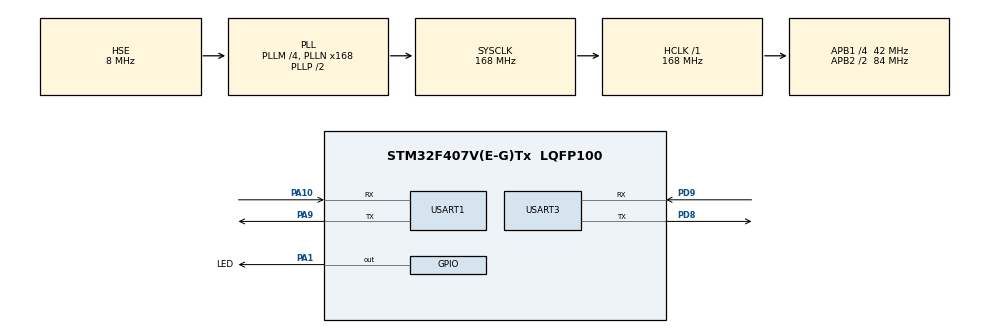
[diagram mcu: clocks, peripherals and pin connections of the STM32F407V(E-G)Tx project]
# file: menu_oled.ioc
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Mcu.Family=STM32F4
Mcu.Name=STM32F407V(E-G)Tx
Mcu.Package=LQFP100
NVIC.PriorityGroup=NVIC_PRIORITYGROUP_4
NVIC.TIM6_DAC_IRQn=true\:0\:0\:false\:false\:true\:true\:true
NVIC.TIM7_IRQn=true\:0\:0\:false\:false\:true\:true\:true
NVIC.USART3_IRQn=true\:0\:0\:false\:false\:true\:true\:true
PA1.GPIO_Label=LED
PA1.Signal=GPIO_Output
PA10.Mode=Asynchronous
PA10.Signal=USART1_RX
PA13.Mode=Serial_Wire
PA13.Signal=SYS_JTMS-SWDIO
PA14.Mode=Serial_Wire
PA14.Signal=SYS_JTCK-SWCLK
PA9.Mode=Asynchronous
PA9.Signal=USART1_TX
PC14-OSC32_IN.Mode=LSE-External-Oscillator
PC14-OSC32_IN.Signal=RCC_OSC32_IN
PC15-OSC32_OUT.Mode=LSE-External-Oscillator
PC15-OSC32_OUT.Signal=RCC_OSC32_OUT
PD8.Mode=Asynchronous
PD8.Signal=USART3_TX
PD9.Mode=Asynchronous
PD9.Signal=USART3_RX
PH0-OSC_IN.Mode=HSE-External-Oscillator
PH0-OSC_IN.Signal=RCC_OSC_IN
PH1-OSC_OUT.Mode=HSE-External-Oscillator
PH1-OSC_OUT.Signal=RCC_OSC_OUT
ProjectManager.HeapSize=0x200
ProjectManager.StackSize=0x1000
ProjectManager.TargetToolchain=MDK-ARM V5.27
RCC.48MHZClocksFreq_Value=48000000
RCC.AHBFreq_Value=168000000
RCC.APB1CLKDivider=RCC_HCLK_DIV4
RCC.APB1Freq_Value=42000000
RCC.APB1TimFreq_Value=84000000
RCC.APB2CLKDivider=RCC_HCLK_DIV2
RCC.APB2Freq_Value=84000000
RCC.APB2TimFreq_Value=168000000
RCC.CortexFreq_Value=168000000
RCC.HCLKFreq_Value=168000000
RCC.HSE_VALUE=8000000
RCC.HSI_VALUE=16000000
RCC.PLLM=4
RCC.PLLN=168
RCC.PLLQ=7
RCC.PLLSourceVirtual=RCC_PLLSOURCE_HSE
RCC.SYSCLKFreq_VALUE=168000000
RCC.SYSCLKSource=RCC_SYSCLKSOURCE_PLLCLK
RCC.VCOOutputFreq_Value=336000000
TIM6.Period=10000
TIM6.Prescaler=83
TIM7.Period=50000
TIM7.Prescaler=83
USART1.VirtualMode=VM_ASYNC
USART3.VirtualMode=VM_ASYNC
VP_RTC_VS_RTC_Activate.Mode=RTC_Enabled
VP_TIM6_VS_ClockSourceINT.Mode=Enable_Timer
VP_TIM7_VS_ClockSourceINT.Mode=Enable_Timer
board=custom

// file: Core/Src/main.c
/* USER CODE BEGIN Header */
/**
  ******************************************************************************
  * @file           : main.c
  * @brief          : Main program body
  ******************************************************************************
  * @attention
  *
  * <h2><center>&copy; Copyright (c) 2021 STMicroelectronics.
  * All rights reserved.</center></h2>
  *
  * This software component is licensed by ST under BSD 3-Clause license,
  * the "License"; You may not use this file except in compliance with the
  * License. You may obtain a copy of the License at:
  *                        opensource.org/licenses/BSD-3-Clause
  *
  ******************************************************************************
  */
/* USER CODE END Header */
#include "main.h"
#include "rtc.h"
#include "tim.h"
#include "usart.h"
#include "gpio.h"
#include "myiic.h"
#include "oled12832.h"
#include "menu.h"

void SystemClock_Config(void);

int main(void)
{

  /* MCU Configuration--------------------------------------------------------*/

  /* Reset of all peripherals, Initializes the Flash interface and the Systick. */
  HAL_Init();

  /* Configure the system clock */
  SystemClock_Config();

  /* Initialize all configured peripherals */
  MX_GPIO_Init();
  MX_USART1_UART_Init();
  MX_TIM7_Init();
  MX_TIM6_Init();
  MX_USART3_UART_Init();
  MX_RTC_Init();
  /* USER CODE BEGIN 2 */
  MyIIC_Init();
  OLED_Init();
  OLED_Clear();
  MenuInit();
  /* USER CODE END 2 */

  /* Infinite loop */
  while (1)
  {

    /* USER CODE BEGIN 3 */
    HAL_Delay(500);
    caidan();
  }
  /* USER CODE END 3 */
}

void SystemClock_Config(void)
{
  RCC_OscInitTypeDef RCC_OscInitStruct = {0};
  RCC_ClkInitTypeDef RCC_ClkInitStruct = {0};
  RCC_PeriphCLKInitTypeDef PeriphClkInitStruct = {0};

  /** Configure the main internal regulator output voltage
  */
  __HAL_RCC_PWR_CLK_ENABLE();
  __HAL_PWR_VOLTAGESCALING_CONFIG(PWR_REGULATOR_VOLTAGE_SCALE1);
  /** Initializes the RCC Oscillators according to the specified parameters
  * in the RCC_OscInitTypeDef structure.
  */
  RCC_OscInitStruct.OscillatorType = RCC_OSCILLATORTYPE_LSI|RCC_OSCILLATORTYPE_HSE;
  RCC_OscInitStruct.HSEState = RCC_HSE_ON;
  RCC_OscInitStruct.LSIState = RCC_LSI_ON;
  RCC_OscInitStruct.PLL.PLLState = RCC_PLL_ON;
  RCC_OscInitStruct.PLL.PLLSource = RCC_PLLSOURCE_HSE;
  RCC_OscInitStruct.PLL.PLLM = 4;
  RCC_OscInitStruct.PLL.PLLN = 168;
  RCC_OscInitStruct.PLL.PLLP = RCC_PLLP_DIV2;
  RCC_OscInitStruct.PLL.PLLQ = 7;
  if (HAL_RCC_OscConfig(&RCC_OscInitStruct) != HAL_OK)
  {
    Error_Handler();
  }
  /** Initializes the CPU, AHB and APB buses clocks
  */
  RCC_ClkInitStruct.ClockType = RCC_CLOCKTYPE_HCLK|RCC_CLOCKTYPE_SYSCLK
                              |RCC_CLOCKTYPE_PCLK1|RCC_CLOCKTYPE_PCLK2;
  RCC_ClkInitStruct.SYSCLKSource = RCC_SYSCLKSOURCE_PLLCLK;
  RCC_ClkInitStruct.AHBCLKDivider = RCC_SYSCLK_DIV1;
  RCC_ClkInitStruct.APB1CLKDivider = RCC_HCLK_DIV4;
  RCC_ClkInitStruct.APB2CLKDivider = RCC_HCLK_DIV2;

  if (HAL_RCC_ClockConfig(&RCC_ClkInitStruct, FLASH_LATENCY_5) != HAL_OK)
  {
    Error_Handler();
  }
  PeriphClkInitStruct.PeriphClockSelection = RCC_PERIPHCLK_RTC;
  PeriphClkInitStruct.RTCClockSelection = RCC_RTCCLKSOURCE_LSI;
  if (HAL_RCCEx_PeriphCLKConfig(&PeriphClkInitStruct) != HAL_OK)
  {
    Error_Handler();
  }
}

void Error_Handler(void)
{
  __disable_irq();
  while (1)
  {
  }
}

/************************ (C) COPYRIGHT STMicroelectronics *****END OF FILE****/
